# 3066MNPIRH register map
File version: 1.0
Registers are 32-bit, access per field, reset 0x0 unless marked. A register's access mark holds for its fields unless they carry their own. Offsets are from the block's base; [hi:lo] are bit positions.

## TIMER0 — TIMER0 peripheral interface
Base 0x14300000
Same registers: TIMER1 0x14301000, TIMER2 0x14302000, TIMER3 0x14303000
0x00 TIMERx_LOAD rw — TIMERx_LOAD为计数初值寄存器。用来配置定时器的计数初值。 向TIMERx_LOAD寄存器写入的最小有效值为1。 当向TIMERx_LOAD写0时，TIMER将会立刻产生1个中断。
  [31:0] timerload — TIMER的计数初值。
0x04 TIMERx_VALUE ro reset 0xFFFFFFFF — TIMERx_VALUE为当前计数值寄存器。用于给出正在递减的计数器的当前值。当向TIMERx_LOAD寄存器的写操作发生后，TIMERx_VALUE立刻反映出计数器的新载入值。
  [31:0] timervalue — TIMERx当前计数值。
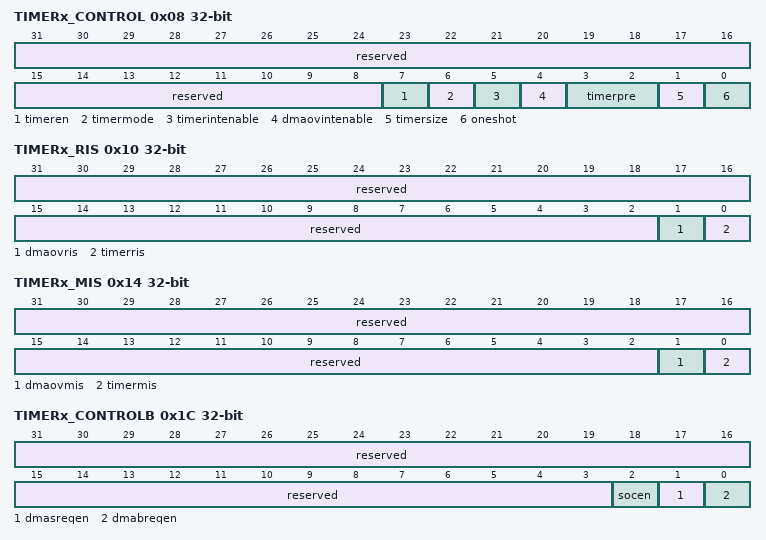
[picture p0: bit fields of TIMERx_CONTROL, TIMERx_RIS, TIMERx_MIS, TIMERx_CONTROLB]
0x08 TIMERx_CONTROL — TIMERx_CONTROL为TIMER控制寄存器。 当选择用周期模式进行计数时，需要将TIMERx_CONTROL.timermode置1、TIMERx_CONTROL.oneshot置0。
  [31:8] reserved ro — 保留。
  [7] timeren rw — 定时器使能。 0：TIMER禁止； 1：TIMER使能。
  [6] timermode rw — 定时器的计数模式。 0：自由运行模式； 1：周期模式。
  [5] timerintenable rw — 定时中断屏蔽。 0：屏蔽该中断； 1：不屏蔽该中断。
  [4] dmaovintenable rw — DMA请求溢出中断屏蔽。 0：屏蔽该中断； 1：不屏蔽该中断。
  [3:2] timerpre rw — 该字段用于设置TIMER的预分频系数。 00：对clk_sys进行1倍预分频； 01：对clk_sys进行16倍预分频； 10：对clk_sys进行256倍预分频； 11：对clk_sys进行256倍预分频。
  [1] timersize rw — 选择16bit/32bit计数器操作模式。 0：16bit计数器； 1：32bit计数器。
  [0] oneshot rw — 选择计数模式为单次计数模式还是周期计数模式。 0：周期计数模式或自由运行模式； 1：单次计数模式。
0x0C TIMERx_INTCLR wo — TIMERx_INTCLR为中断清除寄存器。对该寄存器的任何写操作都会清除相应计数器的中断状态。 本寄存器是只写寄存器，写进去任意值，都会引起TIMER清中断。
  [31:0] timerintclr — 写该寄存器，清除TIMERx的中断输出。
0x10 TIMERx_RIS ro — TIMERx_RIS为原始中断寄存器。
  [31:2] reserved — 保留。
  [1] dmaovris — DMA请求溢出中断的原始中断状态。 0：未产生中断； 1：已产生中断。
  [0] timerris — 定时中断的原始中断状态。 0：未产生中断； 1：已产生中断。
0x14 TIMERx_MIS ro — TIMERx_MIS为屏蔽后中断寄存器。
  [31:2] reserved — 保留。
  [1] dmaovmis — 屏蔽后的DMA请求溢出中断状态。 0：中断无效； 1：中断有效。
  [0] timermis — 屏蔽后的定时中断状态。 0：中断无效； 1：中断有效。
0x18 TIMERx_BGLOAD rw — TIMERx_BGLOAD为计数周期值寄存器。
  [31:0] timerbgload — TIMERx的计数周期值。
0x1C TIMERx_CONTROLB — TIMERx_CONTROLB为TIMER的DMA/ADC控制寄存器。
  [31:3] reserved ro — 保留。
  [2] socen rw — 触发ADC采样信号（SOC信号）使能位。 0：计数器计到0时禁止产生SOC信号； 1：计数器计到0时可以产生SOC信号。
  [1] dmasreqen rw — DMA Single请求使能位。 0：计数器计到0时禁止产生DMA Single请求； 1：计数器计到0时可以产生DMA Single请求。
  [0] dmabreqen rw — DMA Burst 请求使能位。 0：计数器计到0时禁止产生DMA Burst请求； 1：计数器计到0时可以产生DMA Burst请求。
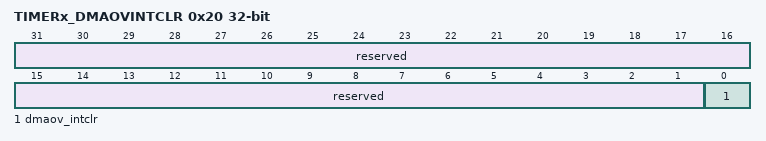
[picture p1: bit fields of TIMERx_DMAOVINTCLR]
0x20 TIMERx_DMAOVINTCLR — TIMERx_DMAOVINTCLR为TIMER的DMA请求溢出中断清除寄存器。
  [31:1] reserved ro — 保留。
  [0] dmaov_intclr wo — DMA请求溢出中断清除位。 0：写0无效； 1：写1清零。

## WWDG_CFG — WWDG_CFG peripheral interface
Base 0x14400000
0x00 WWDG_LOAD 16-bit rw reset 0xFFFF — WWDG_LOAD为计数初值寄存器。
  [15:0] wwdg_load — 计数初值。
0x04 WWDG_VALUE 16-bit ro reset 0xFFFF — WWDG_VALUE为计数器当前值寄存器。
  [15:0] wwdg_value — WatchDog计数器当前值。
0x08 WWDG_WINDOW 16-bit rw reset 0xFFFF — WWDG_WINDOW为窗口值寄存器。
  [15:0] wwdg_window — 窗口值，禁止大于计数初值寄存器，否则会产生预期之外的动作。
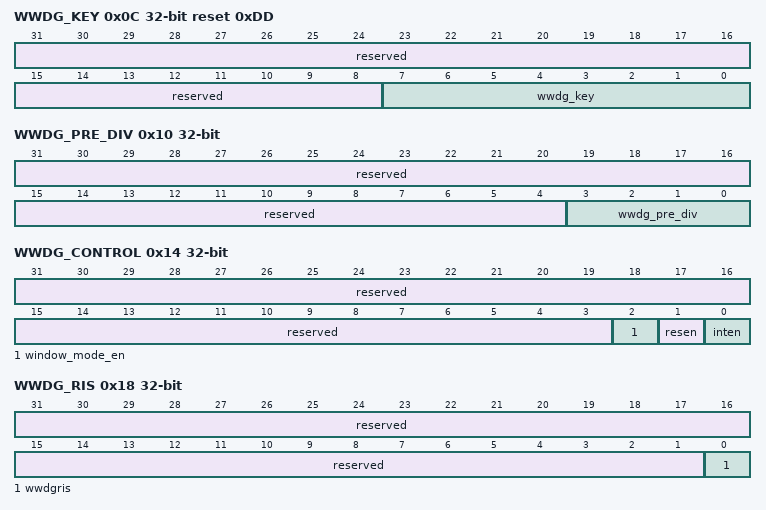
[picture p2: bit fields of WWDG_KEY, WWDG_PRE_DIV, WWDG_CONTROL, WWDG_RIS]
0x0C WWDG_KEY reset 0xDD — WWDG_KEY为指令字寄存器。
  [31:8] reserved ro — 保留。
  [7:0] wwdg_key rw — 对该寄存器写入0xAA使WatchDog从寄存器WWDG_LOAD中重新载入初值计数（喂狗），并可清除WatchDog的中断。 向该寄存器写入0x55，可打开所有可写寄存器的写权限； 向该寄存器写入其他值，关闭所有可写寄存器写权限；本寄存器始终写有效； 向该寄存器写入0xCC，可开启WWDG； 向该寄存器写入0xDD，可关闭WWDG。
0x10 WWDG_PRE_DIV access not given — WWDG_PRE_DIV为预分频寄存器。
  [31:4] reserved ro — 保留。
  [3:0] wwdg_pre_div — 工作时钟的2的幂次分频。受WWDG_KEY.WWDG_key的写权限控制。 0x0：4分频； 0x1：8分频； 0x2：16分频： 0x3：32分频； 0x4：64分频； 0x5：128分频； 0x6：256分频； 0x7：512分频； 0x8：1024分频； 0x9：2048分频； 0xA：4096分频； 0xB：8192分频； 其他：8192分频。
0x14 WWDG_CONTROL — WWDG_CONTROL为控制寄存器。
  [31:3] reserved ro — 保留。
  [2] window_mode_en rw — WatchDog窗口模式使能。 0：禁止； 1：使能。 当禁止窗口模式时，无需设置wwdg_window，中断固定在wwdg_load/2处产生，此时在任意时刻喂狗均不会触发复位信号，复位信号只有在计数值为0且未清除中断时才会产生。 当使能窗口模式时，wwdg_window值生效，中断在计数器值等于窗口值时产生，在窗口值之外喂狗会产生复位信号，在计数为0且未清除中断时也会产生复位信号。
  [1] resen rw — WatchDog复位信号输出使能。 0：禁止； 1：使能。
  [0] inten rw — WatchDog中断信号输出使能。 0：禁止wwdgmis产生； 1：使能wwdgmis。
0x18 WWDG_RIS ro — WWDG_RIS为原始中断标志寄存器。
  [31:1] reserved — 保留。
  [0] wwdgris — WatchDog原始中断状态。 0：未产生中断； 1：已产生中断。
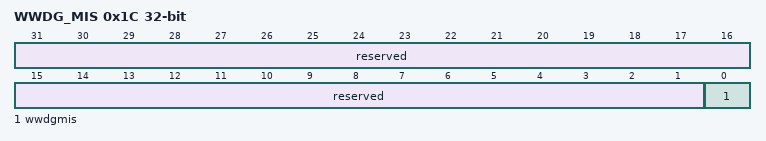
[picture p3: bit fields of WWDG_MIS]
0x1C WWDG_MIS ro — WWDG_MIS为屏蔽后中断标志寄存器。
  [31:1] reserved — 保留。
  [0] wwdgmis — WatchDog屏蔽后的中断状态。 0：未产生中断或者中断被屏蔽； 1：已产生中断。

## IWDG_CFG — IWDG_CFG peripheral interface
Base 0x14401000
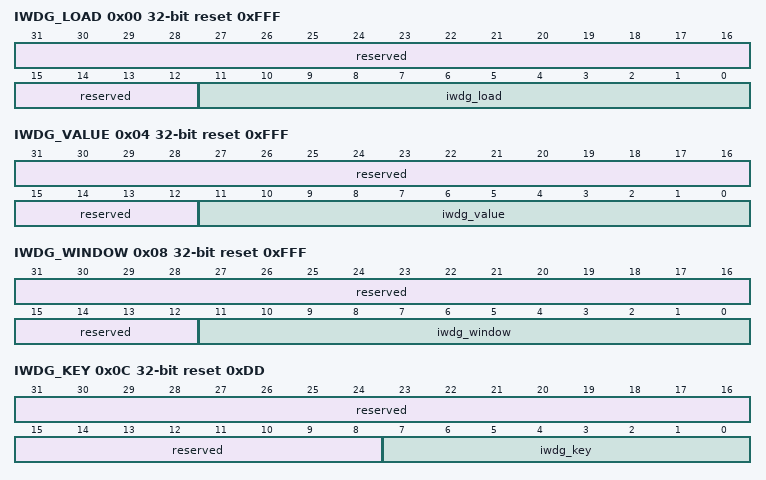
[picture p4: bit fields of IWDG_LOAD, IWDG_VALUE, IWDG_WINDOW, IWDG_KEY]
0x00 IWDG_LOAD reset 0xFFF — IWDG_LOAD为计数初值寄存器。
  [31:12] reserved ro — 保留。
  [11:0] iwdg_load rw — 计数初值。
0x04 IWDG_VALUE ro reset 0xFFF — IWDG_VALUE为计数器当前值寄存器。
  [31:12] reserved — 保留。
  [11:0] iwdg_value — WatchDog计数器当前值，读出值延后于实际计数器的当前值约50us。
0x08 IWDG_WINDOW reset 0xFFF — IWDG_WINDOW为窗口值寄存器。
  [31:12] reserved ro — 保留。
  [11:0] iwdg_window rw — 窗口值，禁止大于计数初值寄存器，否则会产生预期之外的动作。 禁止配置窗口值小于等于4，否则喂狗指令不会及时生效，会导致IWDG复位。
0x0C IWDG_KEY reset 0xDD — IWDG_KEY为指令字寄存器。
  [31:8] reserved ro — 保留。
  [7:0] iwdg_key rw — 对该寄存器写入0xAA使WatchDog从寄存器IWDG_LOAD中重新载入初值计数（喂狗），并可清除WatchDog的中断。 向该寄存器写入0x55，可打开所有可写寄存器的写权限； 向该寄存器写入其他值，关闭所有可写寄存器写权限；本寄存器始终写有效； 向该寄存器写入0xCC，可开启IWDG； 向该寄存器写入0xDD，可关闭IWDG。
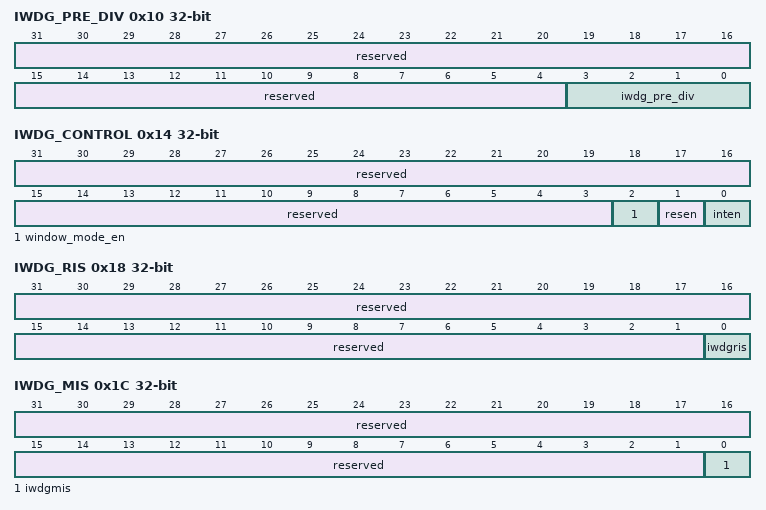
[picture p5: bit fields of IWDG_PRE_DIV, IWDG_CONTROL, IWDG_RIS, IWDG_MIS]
0x10 IWDG_PRE_DIV access not given — IWDG_PRE_DIV为预分频寄存器。
  [31:4] reserved ro — 保留。
  [3:0] iwdg_pre_div — 工作时钟的2的幂次分频。受WWDG_KEY.WWDG_key的写权限控制。 0x0：4分频； 0x1：8分频； 0x2：16分频： 0x3：32分频； 0x4：64分频； 0x5：128分频； 0x6：256分频； 0x7：512分频； 0x8：1024分频； 0x9：2048分频； 0xA：4096分频； 0xB：8192分频； 其他：8192分频。
0x14 IWDG_CONTROL — IWDG_CONTROL为控制寄存器。
  [31:3] reserved ro — 保留。
  [2] window_mode_en rw — WatchDog窗口模式使能。 0：禁止； 1：使能。 当禁止窗口模式时，无需设置iwdg_window，中断固定在iwdg_load/2处产生，此时在任意时刻喂狗均不会触发复位信号，复位信号只有在计数值为0且未清除中断时才会产生。 当使能窗口模式时，iwdg_window值生效，中断在计数器值等于窗口值时产生，在窗口值之外喂狗会产生复位信号，在计数为0且未清除中断时也会产生复位信号。
  [1] resen rw — WatchDog复位信号输出使能。 0：禁止； 1：使能。
  [0] inten rw — WatchDog中断信号输出使能。 0：禁止iwdgmis产生； 1：使能iwdgmis。
0x18 IWDG_RIS ro — IWDG_RIS为原始中断标志寄存器。
  [31:1] reserved — 保留。
  [0] iwdgris — WatchDog原始中断状态。 0：未产生中断； 1：已产生中断。
0x1C IWDG_MIS ro — IWDG_MIS为屏蔽后中断标志寄存器。
  [31:1] reserved — 保留。
  [0] iwdgmis — WatchDog屏蔽后的中断状态。 0：未产生中断或者中断被屏蔽； 1：已产生中断。
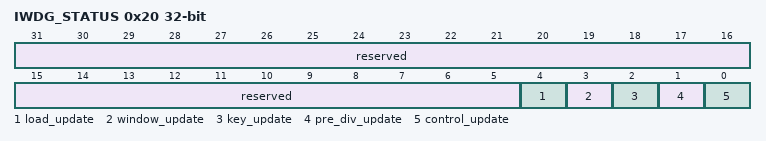
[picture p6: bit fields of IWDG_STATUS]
0x20 IWDG_STATUS ro — IWDG_STATUS为状态寄存器。
  [31:5] reserved — 保留。
  [4] load_update — IWDG_LOAD寄存器更新状态。 0：硬件更新完毕后，自动清0； 1：软件写IWDOG_LOAD寄存器，load_update置1。只有当load_update为0时，软件才能更新IWDG_LOAD寄存器。
  [3] window_update — IWDG_WINDOW寄存器更新状态。 0：硬件更新完毕后，自动清0； 1：软件写IWDOG_WINDOW寄存器，置1。只有当window_update为0时，软件才能更新IWDG_WINDOW寄存器。
  [2] key_update — IWDG_KEY寄存器更新状态。 0：硬件更新完毕后，自动清0； 1：软件写IWDOG_KEY寄存器，置1。只有当key_update为0时，软件才能更新IWDG_KEY寄存器。
  [1] pre_div_update — IWDG_PRE_DIV寄存器更新状态。 0：硬件更新完毕后，自动清0； 1：软件写IWDOG_PRE_DIV寄存器，置1。只有当pre_div_update为0时，软件才能更新IWDG_PRE_DIV寄存器。
  [0] control_update — IWDG_CONTROL寄存器更新状态。 0：硬件更新完毕后，自动清0； 1：软件写IWDOG_CONTROL寄存器，置1。只有当control_update为0时，软件才能更新IWDG_CONTROL寄存器。
